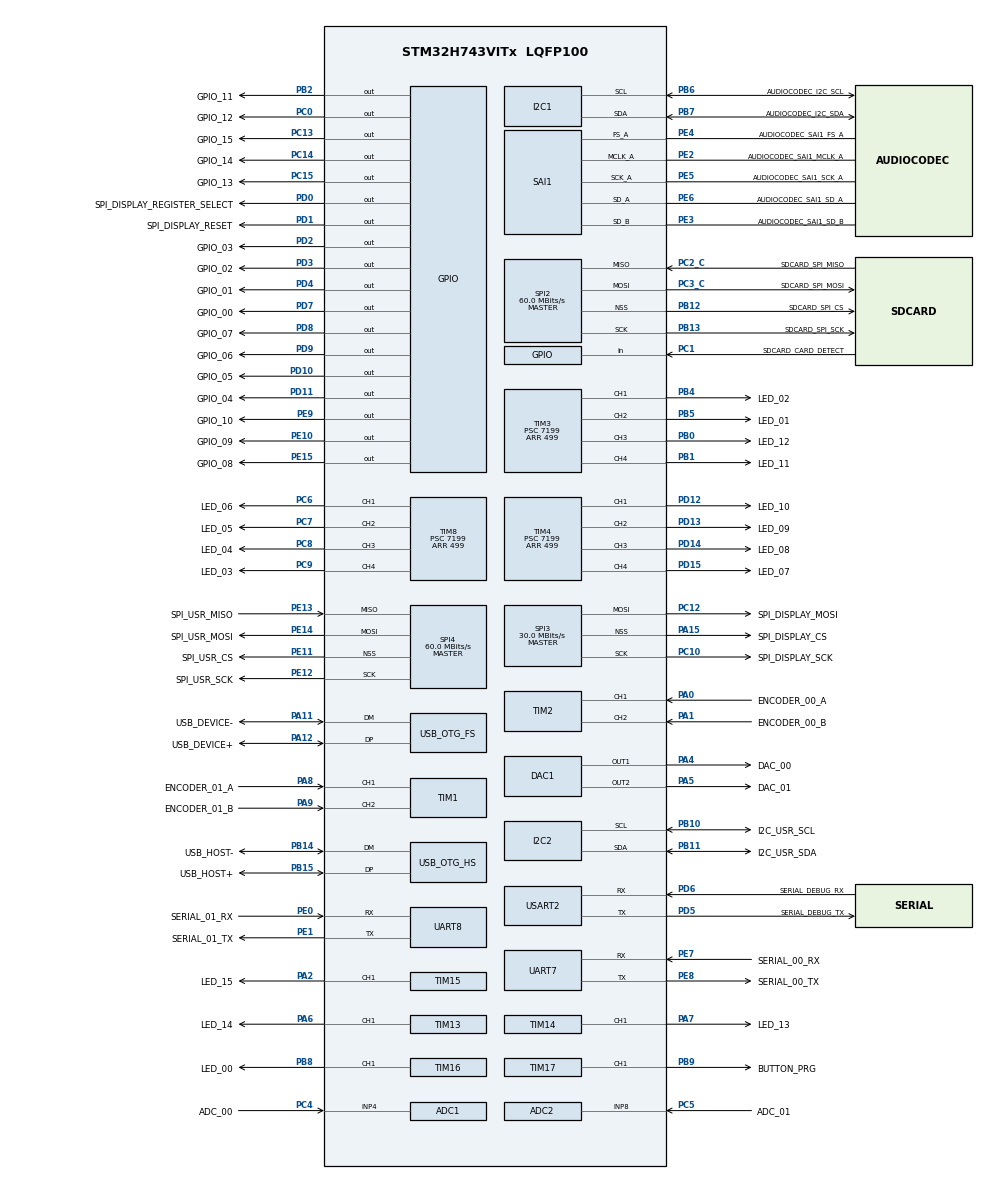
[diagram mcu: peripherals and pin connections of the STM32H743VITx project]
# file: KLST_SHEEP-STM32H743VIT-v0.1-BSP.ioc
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ADC1.Channel-5\#ChannelRegularConversion=ADC_CHANNEL_4
ADC1.NbrOfConversionFlag=1
ADC1.OffsetNumber-5\#ChannelRegularConversion=ADC_OFFSET_NONE
ADC1.OffsetSignedSaturation-5\#ChannelRegularConversion=DISABLE
ADC1.Rank-5\#ChannelRegularConversion=1
ADC1.SamplingTime-5\#ChannelRegularConversion=ADC_SAMPLETIME_1CYCLE_5
ADC1.master=1
ADC2.Channel-4\#ChannelRegularConversion=ADC_CHANNEL_8
ADC2.NbrOfConversionFlag=1
ADC2.OffsetNumber-4\#ChannelRegularConversion=ADC_OFFSET_NONE
ADC2.OffsetSignedSaturation-4\#ChannelRegularConversion=DISABLE
ADC2.Rank-4\#ChannelRegularConversion=1
ADC2.SamplingTime-4\#ChannelRegularConversion=ADC_SAMPLETIME_1CYCLE_5
DAC1.DAC_Channel-DAC_OUT1=DAC_CHANNEL_1
DAC1.DAC_Channel-DAC_OUT2=DAC_CHANNEL_2
Dma.Request0=SAI1_A
Dma.Request1=SAI1_B
Dma.Request2=SPI3_TX
Dma.SAI1_A.0.Direction=DMA_MEMORY_TO_PERIPH
Dma.SAI1_A.0.EventEnable=DISABLE
Dma.SAI1_A.0.FIFOMode=DMA_FIFOMODE_DISABLE
Dma.SAI1_A.0.Instance=DMA1_Stream0
Dma.SAI1_A.0.MemDataAlignment=DMA_MDATAALIGN_HALFWORD
Dma.SAI1_A.0.MemInc=DMA_MINC_ENABLE
Dma.SAI1_A.0.Mode=DMA_CIRCULAR
Dma.SAI1_A.0.PeriphDataAlignment=DMA_PDATAALIGN_HALFWORD
Dma.SAI1_A.0.PeriphInc=DMA_PINC_DISABLE
Dma.SAI1_A.0.Polarity=HAL_DMAMUX_REQ_GEN_RISING
Dma.SAI1_A.0.Priority=DMA_PRIORITY_LOW
Dma.SAI1_A.0.RequestNumber=1
Dma.SAI1_A.0.SignalID=NONE
Dma.SAI1_A.0.SyncEnable=DISABLE
Dma.SAI1_A.0.SyncPolarity=HAL_DMAMUX_SYNC_NO_EVENT
Dma.SAI1_A.0.SyncRequestNumber=1
Dma.SAI1_A.0.SyncSignalID=NONE
Dma.SAI1_B.1.Direction=DMA_PERIPH_TO_MEMORY
Dma.SAI1_B.1.EventEnable=DISABLE
Dma.SAI1_B.1.FIFOMode=DMA_FIFOMODE_DISABLE
Dma.SAI1_B.1.Instance=DMA1_Stream1
Dma.SAI1_B.1.MemDataAlignment=DMA_MDATAALIGN_HALFWORD
Dma.SAI1_B.1.MemInc=DMA_MINC_ENABLE
Dma.SAI1_B.1.Mode=DMA_CIRCULAR
Dma.SAI1_B.1.PeriphDataAlignment=DMA_PDATAALIGN_HALFWORD
Dma.SAI1_B.1.PeriphInc=DMA_PINC_DISABLE
Dma.SAI1_B.1.Polarity=HAL_DMAMUX_REQ_GEN_RISING
Dma.SAI1_B.1.Priority=DMA_PRIORITY_LOW
Dma.SAI1_B.1.RequestNumber=1
Dma.SAI1_B.1.SignalID=NONE
Dma.SAI1_B.1.SyncEnable=DISABLE
Dma.SAI1_B.1.SyncPolarity=HAL_DMAMUX_SYNC_NO_EVENT
Dma.SAI1_B.1.SyncRequestNumber=1
Dma.SAI1_B.1.SyncSignalID=NONE
Dma.SPI3_TX.2.Direction=DMA_MEMORY_TO_PERIPH
Dma.SPI3_TX.2.EventEnable=DISABLE
Dma.SPI3_TX.2.FIFOMode=DMA_FIFOMODE_DISABLE
Dma.SPI3_TX.2.Instance=DMA2_Stream0
Dma.SPI3_TX.2.MemDataAlignment=DMA_MDATAALIGN_BYTE
Dma.SPI3_TX.2.MemInc=DMA_MINC_ENABLE
Dma.SPI3_TX.2.Mode=DMA_NORMAL
Dma.SPI3_TX.2.PeriphDataAlignment=DMA_PDATAALIGN_BYTE
Dma.SPI3_TX.2.PeriphInc=DMA_PINC_DISABLE
Dma.SPI3_TX.2.Polarity=HAL_DMAMUX_REQ_GEN_RISING
Dma.SPI3_TX.2.Priority=DMA_PRIORITY_LOW
Dma.SPI3_TX.2.RequestNumber=1
Dma.SPI3_TX.2.SignalID=NONE
Dma.SPI3_TX.2.SyncEnable=DISABLE
Dma.SPI3_TX.2.SyncPolarity=HAL_DMAMUX_SYNC_NO_EVENT
Dma.SPI3_TX.2.SyncRequestNumber=1
Dma.SPI3_TX.2.SyncSignalID=NONE
Mcu.Family=STM32H7
Mcu.Name=STM32H743VITx
Mcu.Package=LQFP100
NVIC.DMA1_Stream0_IRQn=true\:0\:0\:false\:false\:true\:false\:true\:true
NVIC.DMA1_Stream1_IRQn=true\:0\:0\:false\:false\:true\:false\:true\:true
NVIC.DMA2_Stream0_IRQn=true\:0\:0\:false\:false\:true\:false\:true\:true
NVIC.OTG_FS_IRQn=true\:0\:0\:false\:false\:true\:false\:true\:true
NVIC.OTG_HS_IRQn=true\:0\:0\:false\:false\:true\:false\:true\:true
NVIC.PriorityGroup=NVIC_PRIORITYGROUP_4
NVIC.SPI3_IRQn=true\:0\:0\:false\:false\:true\:false\:true\:true
PA0.GPIO_Label=ENCODER_00_A
PA0.Signal=S_TIM2_CH1_ETR
PA1.GPIO_Label=ENCODER_00_B
PA1.Signal=S_TIM2_CH2
PA10.GPIO_Label=ENCODER_01_BUTTON
PA10.Signal=S_TIM1_CH3
PA11.GPIO_Label=USB_DEVICE-
PA11.Mode=Device_Only
PA11.Signal=USB_OTG_FS_DM
PA12.GPIO_Label=USB_DEVICE+
PA12.Mode=Device_Only
PA12.Signal=USB_OTG_FS_DP
PA13\ (JTMS/SWDIO).GPIO_Label=SWD_SWDIO
PA13\ (JTMS/SWDIO).Mode=Trace_Asynchronous_SW
PA13\ (JTMS/SWDIO).Signal=DEBUG_JTMS-SWDIO
PA14\ (JTCK/SWCLK).GPIO_Label=SWD_SWCLK
PA14\ (JTCK/SWCLK).Mode=Trace_Asynchronous_SW
PA14\ (JTCK/SWCLK).Signal=DEBUG_JTCK-SWCLK
PA15\ (JTDI).GPIO_Label=SPI_DISPLAY_CS
PA15\ (JTDI).Mode=NSS_Signal_Hard_Output
PA15\ (JTDI).Signal=SPI3_NSS
PA2.GPIO_Label=LED_15
PA2.Signal=S_TIM15_CH1
PA3.GPIO_Label=ENCODER_00_BUTTON
PA3.Signal=S_TIM2_CH4
PA4.GPIO_Label=DAC_00
PA4.Signal=COMP_DAC11_group
PA5.GPIO_Label=DAC_01
PA5.Signal=COMP_DAC12_group
PA6.GPIO_Label=LED_14
PA6.Signal=S_TIM13_CH1
PA7.GPIO_Label=LED_13
PA7.Signal=S_TIM14_CH1
PA8.GPIO_Label=ENCODER_01_A
PA8.Signal=S_TIM1_CH1
PA9.GPIO_Label=ENCODER_01_B
PA9.Signal=S_TIM1_CH2
PB0.GPIO_Label=LED_12
PB0.Signal=S_TIM3_CH3
PB1.GPIO_Label=LED_11
PB1.Signal=S_TIM3_CH4
PB10.GPIO_Label=I2C_USR_SCL
PB10.GPIO_Pu=GPIO_PULLUP
PB10.Mode=I2C
PB10.Signal=I2C2_SCL
PB11.GPIO_Label=I2C_USR_SDA
PB11.GPIO_Pu=GPIO_NOPULL
PB11.Mode=I2C
PB11.Signal=I2C2_SDA
PB12.GPIO_Label=SDCARD_SPI_CS
PB12.Mode=NSS_Signal_Hard_Output
PB12.Signal=SPI2_NSS
PB13.GPIO_Label=SDCARD_SPI_SCK
PB13.Mode=Full_Duplex_Master
PB13.Signal=SPI2_SCK
PB14.GPIO_Label=USB_HOST-
PB14.Mode=Host_FS
PB14.Signal=USB_OTG_HS_DM
PB15.GPIO_Label=USB_HOST+
PB15.Mode=Host_FS
PB15.Signal=USB_OTG_HS_DP
PB2.GPIO_Label=GPIO_11
PB2.Signal=GPIO_Output
PB3\ (JTDO/TRACESWO).GPIO_Label=SWD_SWO
PB3\ (JTDO/TRACESWO).Mode=Trace_Asynchronous_SW
PB3\ (JTDO/TRACESWO).Signal=DEBUG_JTDO-SWO
PB4\ (NJTRST).GPIO_Label=LED_02
PB4\ (NJTRST).Signal=S_TIM3_CH1
PB5.GPIO_Label=LED_01
PB5.Signal=S_TIM3_CH2
PB6.GPIO_Label=AUDIOCODEC_I2C_SCL
PB6.GPIO_Pu=GPIO_PULLUP
PB6.GPIO_Speed=GPIO_SPEED_FREQ_HIGH
PB6.Mode=I2C
PB6.Signal=I2C1_SCL
PB7.GPIO_Label=AUDIOCODEC_I2C_SDA
PB7.GPIO_Pu=GPIO_PULLUP
PB7.GPIO_Speed=GPIO_SPEED_FREQ_HIGH
PB7.Mode=I2C
PB7.Signal=I2C1_SDA
PB8.GPIO_Label=LED_00
PB8.Signal=S_TIM16_CH1
PB9.GPIO_Label=BUTTON_PRG
PB9.Signal=S_TIM17_CH1
PC0.GPIO_Label=GPIO_12
PC0.Signal=GPIO_Output
PC1.GPIO_Label=SDCARD_CARD_DETECT
PC1.Signal=GPIO_Input
PC10.GPIO_Label=SPI_DISPLAY_SCK
PC10.Mode=TX_Only_Simplex_Unidirect_Master
PC10.Signal=SPI3_SCK
PC11.GPIO_Label=SPI_DISPLAY_MISO
PC11.Signal=SPI3_MISO
PC12.GPIO_Label=SPI_DISPLAY_MOSI
PC12.Mode=TX_Only_Simplex_Unidirect_Master
PC12.Signal=SPI3_MOSI
PC13.GPIO_Label=GPIO_15
PC13.Signal=GPIO_Output
PC14-OSC32_IN\ (OSC32_IN).GPIO_Label=GPIO_14
PC14-OSC32_IN\ (OSC32_IN).Signal=GPIO_Output
PC15-OSC32_OUT\ (OSC32_OUT).GPIO_Label=GPIO_13
PC15-OSC32_OUT\ (OSC32_OUT).Signal=GPIO_Output
PC2_C.GPIO_Label=SDCARD_SPI_MISO
PC2_C.Mode=Full_Duplex_Master
PC2_C.Signal=SPI2_MISO
PC3_C.GPIO_Label=SDCARD_SPI_MOSI
PC3_C.Mode=Full_Duplex_Master
PC3_C.Signal=SPI2_MOSI
PC4.GPIO_Label=ADC_00
PC4.Signal=ADCx_INP4
PC5.GPIO_Label=ADC_01
PC5.Signal=ADCx_INP8
PC6.GPIO_Label=LED_06
PC6.Signal=S_TIM8_CH1
PC7.GPIO_Label=LED_05
PC7.Signal=S_TIM8_CH2
PC8.GPIO_Label=LED_04
PC8.Signal=S_TIM8_CH3
PC9.GPIO_Label=LED_03
PC9.Signal=S_TIM8_CH4
PD0.GPIO_Label=SPI_DISPLAY_REGISTER_SELECT
PD0.Signal=GPIO_Output
PD1.GPIO_Label=SPI_DISPLAY_RESET
PD1.Signal=GPIO_Output
PD10.GPIO_Label=GPIO_05
PD10.Signal=GPIO_Output
PD11.GPIO_Label=GPIO_04
PD11.Signal=GPIO_Output
PD12.GPIO_Label=LED_10
PD12.Signal=S_TIM4_CH1
PD13.GPIO_Label=LED_09
PD13.Signal=S_TIM4_CH2
PD14.GPIO_Label=LED_08
PD14.Signal=S_TIM4_CH3
PD15.GPIO_Label=LED_07
PD15.Signal=S_TIM4_CH4
PD2.GPIO_Label=GPIO_03
PD2.Signal=GPIO_Output
PD3.GPIO_Label=GPIO_02
PD3.Signal=GPIO_Output
PD4.GPIO_Label=GPIO_01
PD4.Signal=GPIO_Output
PD5.GPIO_Label=SERIAL_DEBUG_TX
PD5.Mode=Asynchronous
PD5.Signal=USART2_TX
PD6.GPIO_Label=SERIAL_DEBUG_RX
PD6.Mode=Asynchronous
PD6.Signal=USART2_RX
PD7.GPIO_Label=GPIO_00
PD7.Signal=GPIO_Output
PD8.GPIO_Label=GPIO_07
PD8.Signal=GPIO_Output
PD9.GPIO_Label=GPIO_06
PD9.Signal=GPIO_Output
PE0.GPIO_Label=SERIAL_01_RX
PE0.Mode=Asynchronous
PE0.Signal=UART8_RX
PE1.GPIO_Label=SERIAL_01_TX
PE1.Mode=Asynchronous
PE1.Signal=UART8_TX
PE10.GPIO_Label=GPIO_09
PE10.Signal=GPIO_Output
PE11.GPIO_Label=SPI_USR_CS
PE11.Mode=NSS_Signal_Hard_Output
PE11.Signal=SPI4_NSS
PE12.GPIO_Label=SPI_USR_SCK
PE12.Mode=Full_Duplex_Master
PE12.Signal=SPI4_SCK
PE13.GPIO_Label=SPI_USR_MISO
PE13.Mode=Full_Duplex_Master
PE13.Signal=SPI4_MISO
PE14.GPIO_Label=SPI_USR_MOSI
PE14.Mode=Full_Duplex_Master
PE14.Signal=SPI4_MOSI
PE15.GPIO_Label=GPIO_08
PE15.Signal=GPIO_Output
PE2.GPIO_Label=AUDIOCODEC_SAI1_MCLK_A
PE2.Mode=SAI_A_MasterWithClock
PE2.Signal=SAI1_MCLK_A
PE3.GPIO_Label=AUDIOCODEC_SAI1_SD_B
PE3.Mode=SAI_B_SyncSlave
PE3.Signal=SAI1_SD_B
PE4.GPIO_Label=AUDIOCODEC_SAI1_FS_A
PE4.Mode=SAI_A_MasterWithClock
PE4.Signal=SAI1_FS_A
PE5.GPIO_Label=AUDIOCODEC_SAI1_SCK_A
PE5.Mode=SAI_A_MasterWithClock
PE5.Signal=SAI1_SCK_A
PE6.GPIO_Label=AUDIOCODEC_SAI1_SD_A
PE6.Mode=SAI_A_MasterWithClock
PE6.Signal=SAI1_SD_A
PE7.GPIO_Label=SERIAL_00_RX
PE7.Mode=Asynchronous
PE7.Signal=UART7_RX
PE8.GPIO_Label=SERIAL_00_TX
PE8.Mode=Asynchronous
PE8.Signal=UART7_TX
PE9.GPIO_Label=GPIO_10
PE9.Signal=GPIO_Output
PH0-OSC_IN\ (PH0).GPIO_Label=RCC_OSC_IN
PH0-OSC_IN\ (PH0).Mode=HSE-External-Oscillator
PH0-OSC_IN\ (PH0).Signal=RCC_OSC_IN
PH1-OSC_OUT\ (PH1).GPIO_Label=RCC_OSC_OUT
PH1-OSC_OUT\ (PH1).Mode=HSE-External-Oscillator
PH1-OSC_OUT\ (PH1).Signal=RCC_OSC_OUT
ProjectManager.HeapSize=0x200
ProjectManager.StackSize=0x400
ProjectManager.TargetToolchain=STM32CubeIDE
RCC.ADCCLockSelection=RCC_ADCCLKSOURCE_PLL3
RCC.ADCFreq_Value=120000000
RCC.APB1Freq_Value=120000000
RCC.APB2Freq_Value=120000000
RCC.APB3Freq_Value=120000000
RCC.APB4Freq_Value=120000000
RCC.CortexFreq_Value=480000000
RCC.D1PPRE=RCC_APB3_DIV2
RCC.D2PPRE1=RCC_APB1_DIV2
RCC.D2PPRE2=RCC_APB2_DIV2
RCC.D3PPRE=RCC_APB4_DIV2
RCC.DIVM1=2
RCC.DIVM2=8
RCC.DIVM3=8
RCC.DIVN1=120
RCC.DIVN2=123
RCC.DIVN3=120
RCC.HCLKFreq_Value=240000000
RCC.HPRE=RCC_HCLK_DIV2
RCC.HSE_VALUE=16000000
RCC.I2C123CLockSelection=RCC_I2C123CLKSOURCE_HSI
RCC.PLL2_VCI_Range-AdvancedSettings=RCC_PLL2VCIRANGE_3
RCC.PLLSourceVirtual=RCC_PLLSOURCE_HSE
RCC.SAI1CLockSelection=RCC_SAI1CLKSOURCE_PLL2
RCC.SAI23CLockSelection=RCC_SAI23CLKSOURCE_PLL3
RCC.SPI123CLockSelection=RCC_SPI123CLKSOURCE_PLL3
RCC.SYSCLKFreq_VALUE=480000000
RCC.SYSCLKSource=RCC_SYSCLKSOURCE_PLLCLK
RCC.Spi45ClockSelection=RCC_SPI45CLKSOURCE_PLL3
RCC.USBCLockSelection=RCC_USBCLKSOURCE_HSI48
RCC.USBFreq_Value=48000000
SAI1.AudioFrequency-SAI_A_MasterWithClock=SAI_AUDIO_FREQUENCY_48K
SAI1.ErrorAudioFreq-SAI_A_MasterWithClock=0.09 %
SAI1.InitProtocol-SAI_A_MasterWithClock=Enable
SAI1.InitProtocol-SAI_B_SyncSlave=Enable
SAI1.Instance-SAI_A_MasterWithClock=SAI$Index_Block_A
SAI1.Instance-SAI_B_SyncSlave=SAI$Index_Block_B
SAI1.MClockEnable=SAI_MASTERCLOCK_ENABLE
SAI1.RealAudioFreq-SAI_A_MasterWithClock=48.046 KHz
SAI1.VirtualMode-SAI_A_MasterWithClock=VM_MASTER
SAI1.VirtualMode-SAI_B_SyncSlave=VM_SLAVE
SAI1.VirtualProtocol-SAI_A_BASIC=VM_BASIC_PROTOCOL
SAI1.VirtualProtocol-SAI_B_BASIC=VM_BASIC_PROTOCOL
SH.ADCx_INP4.0=ADC1_INP4,IN4-Single-Ended
SH.ADCx_INP8.0=ADC2_INP8,IN8-Single-Ended
SH.COMP_DAC11_group.0=DAC1_OUT1,DAC_OUT1
SH.COMP_DAC12_group.0=DAC1_OUT2,DAC_OUT2
SH.S_TIM13_CH1.0=TIM13_CH1,PWM Generation1 CH1
SH.S_TIM14_CH1.0=TIM14_CH1,PWM Generation1 CH1
SH.S_TIM15_CH1.0=TIM15_CH1,PWM Generation1 CH1
SH.S_TIM16_CH1.0=TIM16_CH1,PWM Generation1 CH1
SH.S_TIM17_CH1.0=TIM17_CH1,PWM Generation1 CH1
SH.S_TIM1_CH1.0=TIM1_CH1,Encoder_Interface
SH.S_TIM1_CH2.0=TIM1_CH2,Encoder_Interface
SH.S_TIM1_CH3.0=TIM1_CH3
SH.S_TIM2_CH1_ETR.0=TIM2_CH1,Encoder_Interface
SH.S_TIM2_CH2.0=TIM2_CH2,Encoder_Interface
SH.S_TIM2_CH4.0=TIM2_CH4
SH.S_TIM3_CH1.0=TIM3_CH1,PWM Generation1 CH1
SH.S_TIM3_CH2.0=TIM3_CH2,PWM Generation2 CH2
SH.S_TIM3_CH3.0=TIM3_CH3,PWM Generation3 CH3
SH.S_TIM3_CH4.0=TIM3_CH4,PWM Generation4 CH4
SH.S_TIM4_CH1.0=TIM4_CH1,PWM Generation1 CH1
SH.S_TIM4_CH2.0=TIM4_CH2,PWM Generation2 CH2
SH.S_TIM4_CH3.0=TIM4_CH3,PWM Generation3 CH3
SH.S_TIM4_CH4.0=TIM4_CH4,PWM Generation4 CH4
SH.S_TIM8_CH1.0=TIM8_CH1,PWM Generation1 CH1
SH.S_TIM8_CH2.0=TIM8_CH2,PWM Generation2 CH2
SH.S_TIM8_CH3.0=TIM8_CH3,PWM Generation3 CH3
SH.S_TIM8_CH4.0=TIM8_CH4,PWM Generation4 CH4
SPI2.BaudRatePrescaler=SPI_BAUDRATEPRESCALER_2
SPI2.CalculateBaudRate=60.0 MBits/s
SPI2.Direction=SPI_DIRECTION_2LINES
SPI2.Mode=SPI_MODE_MASTER
SPI2.VirtualNSS=VM_NSSHARD
SPI2.VirtualType=VM_MASTER
SPI3.BaudRatePrescaler=SPI_BAUDRATEPRESCALER_4
SPI3.CalculateBaudRate=30.0 MBits/s
SPI3.DataSize=SPI_DATASIZE_8BIT
SPI3.Direction=SPI_DIRECTION_2LINES_TXONLY
SPI3.MasterKeepIOState=SPI_MASTER_KEEP_IO_STATE_ENABLE
SPI3.Mode=SPI_MODE_MASTER
SPI3.VirtualNSS=VM_NSSHARD
SPI3.VirtualType=VM_MASTER
SPI4.CalculateBaudRate=60.0 MBits/s
SPI4.Direction=SPI_DIRECTION_2LINES
SPI4.Mode=SPI_MODE_MASTER
SPI4.VirtualNSS=VM_NSSHARD
SPI4.VirtualType=VM_MASTER
TIM1.IC1Filter=7
TIM1.IC2Filter=7
TIM13.Channel=TIM_CHANNEL_1
TIM13.Period=499
TIM13.Prescaler=7199
TIM14.Channel=TIM_CHANNEL_1
TIM14.Period=499
TIM14.Prescaler=7199
TIM15.Channel-PWM\ Generation1\ CH1=TIM_CHANNEL_1
TIM15.Period=499
TIM15.Prescaler=7199
TIM16.Channel=TIM_CHANNEL_1
TIM16.OCIdleState_1=TIM_OCIDLESTATE_SET
TIM16.Period=499
TIM16.Prescaler=7199
TIM16.Pulse=250
TIM17.Channel=TIM_CHANNEL_1
TIM2.IC1Filter=7
TIM2.IC2Filter=7
TIM3.Channel-PWM\ Generation1\ CH1=TIM_CHANNEL_1
TIM3.Channel-PWM\ Generation2\ CH2=TIM_CHANNEL_2
TIM3.Channel-PWM\ Generation3\ CH3=TIM_CHANNEL_3
TIM3.Channel-PWM\ Generation4\ CH4=TIM_CHANNEL_4
TIM3.Period=499
TIM3.Prescaler=7199
TIM4.Channel-PWM\ Generation1\ CH1=TIM_CHANNEL_1
TIM4.Channel-PWM\ Generation2\ CH2=TIM_CHANNEL_2
TIM4.Channel-PWM\ Generation3\ CH3=TIM_CHANNEL_3
TIM4.Channel-PWM\ Generation4\ CH4=TIM_CHANNEL_4
TIM4.Period=499
TIM4.Prescaler=7199
TIM8.Channel-PWM\ Generation1\ CH1=TIM_CHANNEL_1
TIM8.Channel-PWM\ Generation2\ CH2=TIM_CHANNEL_2
TIM8.Channel-PWM\ Generation3\ CH3=TIM_CHANNEL_3
TIM8.Channel-PWM\ Generation4\ CH4=TIM_CHANNEL_4
TIM8.Period=499
TIM8.Prescaler=7199
USART2.VirtualMode-Asynchronous=VM_ASYNC
USB_DEVICE.CLASS_NAME_FS=HID
USB_DEVICE.USBD_DEBUG_LEVEL-HID_FS=3
USB_DEVICE.VirtualMode-HID_FS=Hid
USB_DEVICE.VirtualModeFS=Hid_FS
USB_HOST.BSP.number=1
USB_HOST.USBH_DEBUG_LEVEL-HID_HS=3
USB_HOST.USBH_HandleTypeDef-HID_HS=hUsbHostHS
USB_HOST.VirtualModeHS=Hid
USB_HOST0.BSP.STBoard=false
USB_HOST0.BSP.api=Unknown
USB_HOST0.BSP.instance=PD7
USB_HOST0.BSP.ip=GPIO
USB_HOST0.BSP.mode=Output
USB_HOST0.BSP.name=Drive_VBUS_HS
USB_HOST0.BSP.solution=PD7
USB_OTG_FS.VirtualMode=Device_Only
USB_OTG_HS.VirtualMode-Host_FS=Host_FS
VP_SAI1_VP_$IpInstance_SAIA_SAI_BASIC.Mode=SAI_A_BASIC
VP_SAI1_VP_$IpInstance_SAIB_SAI_BASIC.Mode=SAI_B_BASIC
VP_TIM13_VS_ClockSourceINT.Mode=Enable_Timer
VP_TIM14_VS_ClockSourceINT.Mode=Enable_Timer
VP_TIM16_VS_ClockSourceINT.Mode=Enable_Timer
VP_TIM17_VS_ClockSourceINT.Mode=Enable_Timer
VP_USB_DEVICE_VS_USB_DEVICE_HID_FS.Mode=HID_FS
VP_USB_HOST_VS_USB_HOST_HID_HS.Mode=HID_HS
board=custom

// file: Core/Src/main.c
/* USER CODE BEGIN Header */
/**
  ******************************************************************************
  * @file           : main.c
  * @brief          : Main program body
  ******************************************************************************
  * @attention
  *
  * <h2><center>&copy; Copyright (c) 2021 STMicroelectronics.
  * All rights reserved.</center></h2>
  *
  * This software component is licensed by ST under BSD 3-Clause license,
  * the "License"; You may not use this file except in compliance with the
  * License. You may obtain a copy of the License at:
  *                        opensource.org/licenses/BSD-3-Clause
  *
  ******************************************************************************
  */
/* USER CODE END Header */
#include "main.h"
#include "usb_device.h"
#include "usb_host.h"

ADC_HandleTypeDef hadc1;
ADC_HandleTypeDef hadc2;

DAC_HandleTypeDef hdac1;

I2C_HandleTypeDef hi2c1;
I2C_HandleTypeDef hi2c2;

SAI_HandleTypeDef hsai_BlockA1;
SAI_HandleTypeDef hsai_BlockB1;
DMA_HandleTypeDef hdma_sai1_a;
DMA_HandleTypeDef hdma_sai1_b;

SPI_HandleTypeDef hspi2;
SPI_HandleTypeDef hspi3;
SPI_HandleTypeDef hspi4;
DMA_HandleTypeDef hdma_spi3_tx;

TIM_HandleTypeDef htim1;
TIM_HandleTypeDef htim2;
TIM_HandleTypeDef htim3;
TIM_HandleTypeDef htim4;
TIM_HandleTypeDef htim8;
TIM_HandleTypeDef htim13;
TIM_HandleTypeDef htim14;
TIM_HandleTypeDef htim15;
TIM_HandleTypeDef htim16;
TIM_HandleTypeDef htim17;

UART_HandleTypeDef huart7;
UART_HandleTypeDef huart8;
UART_HandleTypeDef huart2;

void SystemClock_Config(void);
void PeriphCommonClock_Config(void);
static void MX_GPIO_Init(void);
static void MX_I2C1_Init(void);
static void MX_SPI2_Init(void);
static void MX_TIM2_Init(void);
static void MX_UART7_Init(void);
static void MX_UART8_Init(void);
static void MX_I2C2_Init(void);
static void MX_SPI4_Init(void);
static void MX_DAC1_Init(void);
static void MX_SAI1_Init(void);
static void MX_TIM1_Init(void);
static void MX_DMA_Init(void);
static void MX_ADC1_Init(void);
static void MX_ADC2_Init(void);
static void MX_TIM4_Init(void);
static void MX_TIM8_Init(void);
static void MX_TIM13_Init(void);
static void MX_TIM14_Init(void);
static void MX_TIM15_Init(void);
static void MX_USART2_UART_Init(void);
static void MX_SPI3_Init(void);
static void MX_TIM3_Init(void);
static void MX_TIM16_Init(void);
static void MX_TIM17_Init(void);
void MX_USB_HOST_Process(void);

/* USER CODE BEGIN PFP */
extern void setup();
extern void loop();
/* USER CODE END PFP */

int main(void)
{

  /* MCU Configuration--------------------------------------------------------*/

  /* Reset of all peripherals, Initializes the Flash interface and the Systick. */
  HAL_Init();

  /* Configure the system clock */
  SystemClock_Config();

/* Configure the peripherals common clocks */
  PeriphCommonClock_Config();

  /* Initialize all configured peripherals */
  MX_GPIO_Init();
  MX_I2C1_Init();
  MX_SPI2_Init();
  MX_TIM2_Init();
  MX_UART7_Init();
  MX_UART8_Init();
  MX_I2C2_Init();
  MX_SPI4_Init();
  MX_DAC1_Init();
  MX_SAI1_Init();
  MX_TIM1_Init();
  MX_DMA_Init();
  MX_ADC1_Init();
  MX_ADC2_Init();
  MX_TIM4_Init();
  MX_TIM8_Init();
  MX_TIM13_Init();
  MX_TIM14_Init();
  MX_TIM15_Init();
  MX_USART2_UART_Init();
  MX_SPI3_Init();
  MX_TIM3_Init();
  MX_TIM16_Init();
  MX_TIM17_Init();
  MX_USB_HOST_Init();
  MX_USB_DEVICE_Init();
  /* USER CODE BEGIN 2 */
  setup();
  /* USER CODE END 2 */

  /* Infinite loop */
  while (1)
  {
    MX_USB_HOST_Process();

    /* USER CODE BEGIN 3 */
	loop();
  }
  /* USER CODE END 3 */
}

void SystemClock_Config(void)
{
  RCC_OscInitTypeDef RCC_OscInitStruct = {0};
  RCC_ClkInitTypeDef RCC_ClkInitStruct = {0};

  /** Supply configuration update enable
  */
  HAL_PWREx_ConfigSupply(PWR_LDO_SUPPLY);

  /** Configure the main internal regulator output voltage
  */
  __HAL_PWR_VOLTAGESCALING_CONFIG(PWR_REGULATOR_VOLTAGE_SCALE1);

  while(!__HAL_PWR_GET_FLAG(PWR_FLAG_VOSRDY)) {}

  __HAL_RCC_SYSCFG_CLK_ENABLE();
  __HAL_PWR_VOLTAGESCALING_CONFIG(PWR_REGULATOR_VOLTAGE_SCALE0);

  while(!__HAL_PWR_GET_FLAG(PWR_FLAG_VOSRDY)) {}

  /** Macro to configure the PLL clock source
  */
  __HAL_RCC_PLL_PLLSOURCE_CONFIG(RCC_PLLSOURCE_HSE);

  /** Initializes the RCC Oscillators according to the specified parameters
  * in the RCC_OscInitTypeDef structure.
  */
  RCC_OscInitStruct.OscillatorType = RCC_OSCILLATORTYPE_HSI48|RCC_OSCILLATORTYPE_HSI
                              |RCC_OSCILLATORTYPE_HSE;
  RCC_OscInitStruct.HSEState = RCC_HSE_ON;
  RCC_OscInitStruct.HSIState = RCC_HSI_DIV1;
  RCC_OscInitStruct.HSICalibrationValue = RCC_HSICALIBRATION_DEFAULT;
  RCC_OscInitStruct.HSI48State = RCC_HSI48_ON;
  RCC_OscInitStruct.PLL.PLLState = RCC_PLL_ON;
  RCC_OscInitStruct.PLL.PLLSource = RCC_PLLSOURCE_HSE;
  RCC_OscInitStruct.PLL.PLLM = 2;
  RCC_OscInitStruct.PLL.PLLN = 120;
  RCC_OscInitStruct.PLL.PLLP = 2;
  RCC_OscInitStruct.PLL.PLLQ = 2;
  RCC_OscInitStruct.PLL.PLLR = 2;
  RCC_OscInitStruct.PLL.PLLRGE = RCC_PLL1VCIRANGE_3;
  RCC_OscInitStruct.PLL.PLLVCOSEL = RCC_PLL1VCOWIDE;
  RCC_OscInitStruct.PLL.PLLFRACN = 0;
  if (HAL_RCC_OscConfig(&RCC_OscInitStruct) != HAL_OK)
  {
    Error_Handler();
  }

  /** Initializes the CPU, AHB and APB buses clocks
  */
  RCC_ClkInitStruct.ClockType = RCC_CLOCKTYPE_HCLK|RCC_CLOCKTYPE_SYSCLK
                              |RCC_CLOCKTYPE_PCLK1|RCC_CLOCKTYPE_PCLK2
                              |RCC_CLOCKTYPE_D3PCLK1|RCC_CLOCKTYPE_D1PCLK1;
  RCC_ClkInitStruct.SYSCLKSource = RCC_SYSCLKSOURCE_PLLCLK;
  RCC_ClkInitStruct.SYSCLKDivider = RCC_SYSCLK_DIV1;
  RCC_ClkInitStruct.AHBCLKDivider = RCC_HCLK_DIV2;
  RCC_ClkInitStruct.APB3CLKDivider = RCC_APB3_DIV2;
  RCC_ClkInitStruct.APB1CLKDivider = RCC_APB1_DIV2;
  RCC_ClkInitStruct.APB2CLKDivider = RCC_APB2_DIV2;
  RCC_ClkInitStruct.APB4CLKDivider = RCC_APB4_DIV2;

  if (HAL_RCC_ClockConfig(&RCC_ClkInitStruct, FLASH_LATENCY_4) != HAL_OK)
  {
    Error_Handler();
  }
}

void PeriphCommonClock_Config(void)
{
  RCC_PeriphCLKInitTypeDef PeriphClkInitStruct = {0};

  /** Initializes the peripherals clock
  */
  PeriphClkInitStruct.PeriphClockSelection = RCC_PERIPHCLK_ADC|RCC_PERIPHCLK_SAI1
                              |RCC_PERIPHCLK_SPI3|RCC_PERIPHCLK_SPI2
                              |RCC_PERIPHCLK_SPI4;
  PeriphClkInitStruct.PLL2.PLL2M = 8;
  PeriphClkInitStruct.PLL2.PLL2N = 123;
  PeriphClkInitStruct.PLL2.PLL2P = 2;
  PeriphClkInitStruct.PLL2.PLL2Q = 2;
  PeriphClkInitStruct.PLL2.PLL2R = 2;
  PeriphClkInitStruct.PLL2.PLL2RGE = RCC_PLL2VCIRANGE_1;
  PeriphClkInitStruct.PLL2.PLL2VCOSEL = RCC_PLL2VCOWIDE;
  PeriphClkInitStruct.PLL2.PLL2FRACN = 0;
  PeriphClkInitStruct.PLL3.PLL3M = 8;
  PeriphClkInitStruct.PLL3.PLL3N = 120;
  PeriphClkInitStruct.PLL3.PLL3P = 2;
  PeriphClkInitStruct.PLL3.PLL3Q = 2;
  PeriphClkInitStruct.PLL3.PLL3R = 2;
  PeriphClkInitStruct.PLL3.PLL3RGE = RCC_PLL3VCIRANGE_1;
  PeriphClkInitStruct.PLL3.PLL3VCOSEL = RCC_PLL3VCOWIDE;
  PeriphClkInitStruct.PLL3.PLL3FRACN = 0;
  PeriphClkInitStruct.Sai1ClockSelection = RCC_SAI1CLKSOURCE_PLL2;
  PeriphClkInitStruct.Spi123ClockSelection = RCC_SPI123CLKSOURCE_PLL3;
  PeriphClkInitStruct.Spi45ClockSelection = RCC_SPI45CLKSOURCE_PLL3;
  PeriphClkInitStruct.AdcClockSelection = RCC_ADCCLKSOURCE_PLL3;
  if (HAL_RCCEx_PeriphCLKConfig(&PeriphClkInitStruct) != HAL_OK)
  {
    Error_Handler();
  }
}

static void MX_ADC1_Init(void)
{

  ADC_MultiModeTypeDef multimode = {0};
  ADC_ChannelConfTypeDef sConfig = {0};

  /** Common config
  */
  hadc1.Instance = ADC1;
  hadc1.Init.ClockPrescaler = ADC_CLOCK_ASYNC_DIV1;
  hadc1.Init.Resolution = ADC_RESOLUTION_16B;
  hadc1.Init.ScanConvMode = ADC_SCAN_DISABLE;
  hadc1.Init.EOCSelection = ADC_EOC_SINGLE_CONV;
  hadc1.Init.LowPowerAutoWait = DISABLE;
  hadc1.Init.ContinuousConvMode = DISABLE;
  hadc1.Init.NbrOfConversion = 1;
  hadc1.Init.DiscontinuousConvMode = DISABLE;
  hadc1.Init.ExternalTrigConv = ADC_SOFTWARE_START;
  hadc1.Init.ExternalTrigConvEdge = ADC_EXTERNALTRIGCONVEDGE_NONE;
  hadc1.Init.ConversionDataManagement = ADC_CONVERSIONDATA_DR;
  hadc1.Init.Overrun = ADC_OVR_DATA_PRESERVED;
  hadc1.Init.LeftBitShift = ADC_LEFTBITSHIFT_NONE;
  hadc1.Init.OversamplingMode = DISABLE;
  if (HAL_ADC_Init(&hadc1) != HAL_OK)
  {
    Error_Handler();
  }

  /** Configure the ADC multi-mode
  */
  multimode.Mode = ADC_MODE_INDEPENDENT;
  if (HAL_ADCEx_MultiModeConfigChannel(&hadc1, &multimode) != HAL_OK)
  {
    Error_Handler();
  }

  /** Configure Regular Channel
  */
  sConfig.Channel = ADC_CHANNEL_4;
  sConfig.Rank = ADC_REGULAR_RANK_1;
  sConfig.SamplingTime = ADC_SAMPLETIME_1CYCLE_5;
  sConfig.SingleDiff = ADC_SINGLE_ENDED;
  sConfig.OffsetNumber = ADC_OFFSET_NONE;
  sConfig.Offset = 0;
  sConfig.OffsetSignedSaturation = DISABLE;
  if (HAL_ADC_ConfigChannel(&hadc1, &sConfig) != HAL_OK)
  {
    Error_Handler();
  }

}

static void MX_ADC2_Init(void)
{

  ADC_ChannelConfTypeDef sConfig = {0};

  /** Common config
  */
  hadc2.Instance = ADC2;
  hadc2.Init.ClockPrescaler = ADC_CLOCK_ASYNC_DIV1;
  hadc2.Init.Resolution = ADC_RESOLUTION_16B;
  hadc2.Init.ScanConvMode = ADC_SCAN_DISABLE;
  hadc2.Init.EOCSelection = ADC_EOC_SINGLE_CONV;
  hadc2.Init.LowPowerAutoWait = DISABLE;
  hadc2.Init.ContinuousConvMode = DISABLE;
  hadc2.Init.NbrOfConversion = 1;
  hadc2.Init.DiscontinuousConvMode = DISABLE;
  hadc2.Init.ExternalTrigConv = ADC_SOFTWARE_START;
  hadc2.Init.ExternalTrigConvEdge = ADC_EXTERNALTRIGCONVEDGE_NONE;
  hadc2.Init.ConversionDataManagement = ADC_CONVERSIONDATA_DR;
  hadc2.Init.Overrun = ADC_OVR_DATA_PRESERVED;
  hadc2.Init.LeftBitShift = ADC_LEFTBITSHIFT_NONE;
  hadc2.Init.OversamplingMode = DISABLE;
  if (HAL_ADC_Init(&hadc2) != HAL_OK)
  {
    Error_Handler();
  }

  /** Configure Regular Channel
  */
  sConfig.Channel = ADC_CHANNEL_8;
  sConfig.Rank = ADC_REGULAR_RANK_1;
  sConfig.SamplingTime = ADC_SAMPLETIME_1CYCLE_5;
  sConfig.SingleDiff = ADC_SINGLE_ENDED;
  sConfig.OffsetNumber = ADC_OFFSET_NONE;
  sConfig.Offset = 0;
  sConfig.OffsetSignedSaturation = DISABLE;
  if (HAL_ADC_ConfigChannel(&hadc2, &sConfig) != HAL_OK)
  {
    Error_Handler();
  }

}

static void MX_DAC1_Init(void)
{

  DAC_ChannelConfTypeDef sConfig = {0};

  /** DAC Initialization
  */
  hdac1.Instance = DAC1;
  if (HAL_DAC_Init(&hdac1) != HAL_OK)
  {
    Error_Handler();
  }

  /** DAC channel OUT1 config
  */
  sConfig.DAC_SampleAndHold = DAC_SAMPLEANDHOLD_DISABLE;
  sConfig.DAC_Trigger = DAC_TRIGGER_NONE;
  sConfig.DAC_OutputBuffer = DAC_OUTPUTBUFFER_ENABLE;
  sConfig.DAC_ConnectOnChipPeripheral = DAC_CHIPCONNECT_DISABLE;
  sConfig.DAC_UserTrimming = DAC_TRIMMING_FACTORY;
  if (HAL_DAC_ConfigChannel(&hdac1, &sConfig, DAC_CHANNEL_1) != HAL_OK)
  {
    Error_Handler();
  }

  /** DAC channel OUT2 config
  */
  if (HAL_DAC_ConfigChannel(&hdac1, &sConfig, DAC_CHANNEL_2) != HAL_OK)
  {
    Error_Handler();
  }

}

static void MX_I2C1_Init(void)
{

  hi2c1.Instance = I2C1;
  hi2c1.Init.Timing = 0x10707DBC;
  hi2c1.Init.OwnAddress1 = 0;
  hi2c1.Init.AddressingMode = I2C_ADDRESSINGMODE_7BIT;
  hi2c1.Init.DualAddressMode = I2C_DUALADDRESS_DISABLE;
  hi2c1.Init.OwnAddress2 = 0;
  hi2c1.Init.OwnAddress2Masks = I2C_OA2_NOMASK;
  hi2c1.Init.GeneralCallMode = I2C_GENERALCALL_DISABLE;
  hi2c1.Init.NoStretchMode = I2C_NOSTRETCH_DISABLE;
  if (HAL_I2C_Init(&hi2c1) != HAL_OK)
  {
    Error_Handler();
  }

  /** Configure Analogue filter
  */
  if (HAL_I2CEx_ConfigAnalogFilter(&hi2c1, I2C_ANALOGFILTER_ENABLE) != HAL_OK)
  {
    Error_Handler();
  }

  /** Configure Digital filter
  */
  if (HAL_I2CEx_ConfigDigitalFilter(&hi2c1, 0) != HAL_OK)
  {
    Error_Handler();
  }

}

static void MX_I2C2_Init(void)
{

  hi2c2.Instance = I2C2;
  hi2c2.Init.Timing = 0x10707DBC;
  hi2c2.Init.OwnAddress1 = 0;
  hi2c2.Init.AddressingMode = I2C_ADDRESSINGMODE_7BIT;
  hi2c2.Init.DualAddressMode = I2C_DUALADDRESS_DISABLE;
  hi2c2.Init.OwnAddress2 = 0;
  hi2c2.Init.OwnAddress2Masks = I2C_OA2_NOMASK;
  hi2c2.Init.GeneralCallMode = I2C_GENERALCALL_DISABLE;
  hi2c2.Init.NoStretchMode = I2C_NOSTRETCH_DISABLE;
  if (HAL_I2C_Init(&hi2c2) != HAL_OK)
  {
    Error_Handler();
  }

  /** Configure Analogue filter
  */
  if (HAL_I2CEx_ConfigAnalogFilter(&hi2c2, I2C_ANALOGFILTER_ENABLE) != HAL_OK)
  {
    Error_Handler();
  }

  /** Configure Digital filter
  */
  if (HAL_I2CEx_ConfigDigitalFilter(&hi2c2, 0) != HAL_OK)
  {
    Error_Handler();
  }

}

static void MX_SAI1_Init(void)
{

  hsai_BlockA1.Instance = SAI1_Block_A;
  hsai_BlockA1.Init.AudioMode = SAI_MODEMASTER_TX;
  hsai_BlockA1.Init.Synchro = SAI_ASYNCHRONOUS;
  hsai_BlockA1.Init.OutputDrive = SAI_OUTPUTDRIVE_DISABLE;
  hsai_BlockA1.Init.NoDivider = SAI_MASTERDIVIDER_ENABLE;
  hsai_BlockA1.Init.FIFOThreshold = SAI_FIFOTHRESHOLD_EMPTY;
  hsai_BlockA1.Init.AudioFrequency = SAI_AUDIO_FREQUENCY_48K;
  hsai_BlockA1.Init.SynchroExt = SAI_SYNCEXT_DISABLE;
  hsai_BlockA1.Init.MonoStereoMode = SAI_STEREOMODE;
  hsai_BlockA1.Init.CompandingMode = SAI_NOCOMPANDING;
  hsai_BlockA1.Init.TriState = SAI_OUTPUT_NOTRELEASED;
  if (HAL_SAI_InitProtocol(&hsai_BlockA1, SAI_I2S_STANDARD, SAI_PROTOCOL_DATASIZE_16BIT, 2) != HAL_OK)
  {
    Error_Handler();
  }
  hsai_BlockB1.Instance = SAI1_Block_B;
  hsai_BlockB1.Init.AudioMode = SAI_MODESLAVE_RX;
  hsai_BlockB1.Init.Synchro = SAI_SYNCHRONOUS;
  hsai_BlockB1.Init.OutputDrive = SAI_OUTPUTDRIVE_DISABLE;
  hsai_BlockB1.Init.FIFOThreshold = SAI_FIFOTHRESHOLD_EMPTY;
  hsai_BlockB1.Init.SynchroExt = SAI_SYNCEXT_DISABLE;
  hsai_BlockB1.Init.MonoStereoMode = SAI_STEREOMODE;
  hsai_BlockB1.Init.CompandingMode = SAI_NOCOMPANDING;
  hsai_BlockB1.Init.TriState = SAI_OUTPUT_NOTRELEASED;
  if (HAL_SAI_InitProtocol(&hsai_BlockB1, SAI_I2S_STANDARD, SAI_PROTOCOL_DATASIZE_16BIT, 2) != HAL_OK)
  {
    Error_Handler();
  }

}

static void MX_SPI2_Init(void)
{

  /* SPI2 parameter configuration*/
  hspi2.Instance = SPI2;
  hspi2.Init.Mode = SPI_MODE_MASTER;
  hspi2.Init.Direction = SPI_DIRECTION_2LINES;
  hspi2.Init.DataSize = SPI_DATASIZE_4BIT;
  hspi2.Init.CLKPolarity = SPI_POLARITY_LOW;
  hspi2.Init.CLKPhase = SPI_PHASE_1EDGE;
  hspi2.Init.NSS = SPI_NSS_HARD_OUTPUT;
  hspi2.Init.BaudRatePrescaler = SPI_BAUDRATEPRESCALER_2;
  hspi2.Init.FirstBit = SPI_FIRSTBIT_MSB;
  hspi2.Init.TIMode = SPI_TIMODE_DISABLE;
  hspi2.Init.CRCCalculation = SPI_CRCCALCULATION_DISABLE;
  hspi2.Init.CRCPolynomial = 0x0;
  hspi2.Init.NSSPMode = SPI_NSS_PULSE_ENABLE;
  hspi2.Init.NSSPolarity = SPI_NSS_POLARITY_LOW;
  hspi2.Init.FifoThreshold = SPI_FIFO_THRESHOLD_01DATA;
  hspi2.Init.TxCRCInitializationPattern = SPI_CRC_INITIALIZATION_ALL_ZERO_PATTERN;
  hspi2.Init.RxCRCInitializationPattern = SPI_CRC_INITIALIZATION_ALL_ZERO_PATTERN;
  hspi2.Init.MasterSSIdleness = SPI_MASTER_SS_IDLENESS_00CYCLE;
  hspi2.Init.MasterInterDataIdleness = SPI_MASTER_INTERDATA_IDLENESS_00CYCLE;
  hspi2.Init.MasterReceiverAutoSusp = SPI_MASTER_RX_AUTOSUSP_DISABLE;
  hspi2.Init.MasterKeepIOState = SPI_MASTER_KEEP_IO_STATE_DISABLE;
  hspi2.Init.IOSwap = SPI_IO_SWAP_DISABLE;
  if (HAL_SPI_Init(&hspi2) != HAL_OK)
  {
    Error_Handler();
  }

}

static void MX_SPI3_Init(void)
{

  /* SPI3 parameter configuration*/
  hspi3.Instance = SPI3;
  hspi3.Init.Mode = SPI_MODE_MASTER;
  hspi3.Init.Direction = SPI_DIRECTION_2LINES_TXONLY;
  hspi3.Init.DataSize = SPI_DATASIZE_8BIT;
  hspi3.Init.CLKPolarity = SPI_POLARITY_LOW;
  hspi3.Init.CLKPhase = SPI_PHASE_1EDGE;
  hspi3.Init.NSS = SPI_NSS_HARD_OUTPUT;
  hspi3.Init.BaudRatePrescaler = SPI_BAUDRATEPRESCALER_4;
  hspi3.Init.FirstBit = SPI_FIRSTBIT_MSB;
  hspi3.Init.TIMode = SPI_TIMODE_DISABLE;
  hspi3.Init.CRCCalculation = SPI_CRCCALCULATION_DISABLE;
  hspi3.Init.CRCPolynomial = 0x0;
  hspi3.Init.NSSPMode = SPI_NSS_PULSE_ENABLE;
  hspi3.Init.NSSPolarity = SPI_NSS_POLARITY_LOW;
  hspi3.Init.FifoThreshold = SPI_FIFO_THRESHOLD_01DATA;
  hspi3.Init.TxCRCInitializationPattern = SPI_CRC_INITIALIZATION_ALL_ZERO_PATTERN;
  hspi3.Init.RxCRCInitializationPattern = SPI_CRC_INITIALIZATION_ALL_ZERO_PATTERN;
  hspi3.Init.MasterSSIdleness = SPI_MASTER_SS_IDLENESS_00CYCLE;
  hspi3.Init.MasterInterDataIdleness = SPI_MASTER_INTERDATA_IDLENESS_00CYCLE;
  hspi3.Init.MasterReceiverAutoSusp = SPI_MASTER_RX_AUTOSUSP_DISABLE;
  hspi3.Init.MasterKeepIOState = SPI_MASTER_KEEP_IO_STATE_ENABLE;
  hspi3.Init.IOSwap = SPI_IO_SWAP_DISABLE;
  if (HAL_SPI_Init(&hspi3) != HAL_OK)
  {
    Error_Handler();
  }

}

static void MX_SPI4_Init(void)
{

  /* SPI4 parameter configuration*/
  hspi4.Instance = SPI4;
  hspi4.Init.Mode = SPI_MODE_MASTER;
  hspi4.Init.Direction = SPI_DIRECTION_2LINES;
  hspi4.Init.DataSize = SPI_DATASIZE_4BIT;
  hspi4.Init.CLKPolarity = SPI_POLARITY_LOW;
  hspi4.Init.CLKPhase = SPI_PHASE_1EDGE;
  hspi4.Init.NSS = SPI_NSS_HARD_OUTPUT;
  hspi4.Init.BaudRatePrescaler = SPI_BAUDRATEPRESCALER_2;
  hspi4.Init.FirstBit = SPI_FIRSTBIT_MSB;
  hspi4.Init.TIMode = SPI_TIMODE_DISABLE;
  hspi4.Init.CRCCalculation = SPI_CRCCALCULATION_DISABLE;
  hspi4.Init.CRCPolynomial = 0x0;
  hspi4.Init.NSSPMode = SPI_NSS_PULSE_ENABLE;
  hspi4.Init.NSSPolarity = SPI_NSS_POLARITY_LOW;
  hspi4.Init.FifoThreshold = SPI_FIFO_THRESHOLD_01DATA;
  hspi4.Init.TxCRCInitializationPattern = SPI_CRC_INITIALIZATION_ALL_ZERO_PATTERN;
  hspi4.Init.RxCRCInitializationPattern = SPI_CRC_INITIALIZATION_ALL_ZERO_PATTERN;
  hspi4.Init.MasterSSIdleness = SPI_MASTER_SS_IDLENESS_00CYCLE;
  hspi4.Init.MasterInterDataIdleness = SPI_MASTER_INTERDATA_IDLENESS_00CYCLE;
  hspi4.Init.MasterReceiverAutoSusp = SPI_MASTER_RX_AUTOSUSP_DISABLE;
  hspi4.Init.MasterKeepIOState = SPI_MASTER_KEEP_IO_STATE_DISABLE;
  hspi4.Init.IOSwap = SPI_IO_SWAP_DISABLE;
  if (HAL_SPI_Init(&hspi4) != HAL_OK)
  {
    Error_Handler();
  }

}

static void MX_TIM1_Init(void)
{

  TIM_Encoder_InitTypeDef sConfig = {0};
  TIM_MasterConfigTypeDef sMasterConfig = {0};

  htim1.Instance = TIM1;
  htim1.Init.Prescaler = 0;
  htim1.Init.CounterMode = TIM_COUNTERMODE_UP;
  htim1.Init.Period = 65535;
  htim1.Init.ClockDivision = TIM_CLOCKDIVISION_DIV1;
  htim1.Init.RepetitionCounter = 0;
  htim1.Init.AutoReloadPreload = TIM_AUTORELOAD_PRELOAD_DISABLE;
  sConfig.EncoderMode = TIM_ENCODERMODE_TI1;
  sConfig.IC1Polarity = TIM_ICPOLARITY_RISING;
  sConfig.IC1Selection = TIM_ICSELECTION_DIRECTTI;
  sConfig.IC1Prescaler = TIM_ICPSC_DIV1;
  sConfig.IC1Filter = 7;
  sConfig.IC2Polarity = TIM_ICPOLARITY_RISING;
  sConfig.IC2Selection = TIM_ICSELECTION_DIRECTTI;
  sConfig.IC2Prescaler = TIM_ICPSC_DIV1;
  sConfig.IC2Filter = 7;
  if (HAL_TIM_Encoder_Init(&htim1, &sConfig) != HAL_OK)
  {
    Error_Handler();
  }
  sMasterConfig.MasterOutputTrigger = TIM_TRGO_RESET;
  sMasterConfig.MasterOutputTrigger2 = TIM_TRGO2_RESET;
  sMasterConfig.MasterSlaveMode = TIM_MASTERSLAVEMODE_DISABLE;
  if (HAL_TIMEx_MasterConfigSynchronization(&htim1, &sMasterConfig) != HAL_OK)
  {
    Error_Handler();
  }

}

static void MX_TIM2_Init(void)
{

  TIM_Encoder_InitTypeDef sConfig = {0};
  TIM_MasterConfigTypeDef sMasterConfig = {0};

  htim2.Instance = TIM2;
  htim2.Init.Prescaler = 0;
  htim2.Init.CounterMode = TIM_COUNTERMODE_UP;
  htim2.Init.Period = 4294967295;
  htim2.Init.ClockDivision = TIM_CLOCKDIVISION_DIV1;
  htim2.Init.AutoReloadPreload = TIM_AUTORELOAD_PRELOAD_DISABLE;
  sConfig.EncoderMode = TIM_ENCODERMODE_TI1;
  sConfig.IC1Polarity = TIM_ICPOLARITY_RISING;
  sConfig.IC1Selection = TIM_ICSELECTION_DIRECTTI;
  sConfig.IC1Prescaler = TIM_ICPSC_DIV1;
  sConfig.IC1Filter = 7;
  sConfig.IC2Polarity = TIM_ICPOLARITY_RISING;
  sConfig.IC2Selection = TIM_ICSELECTION_DIRECTTI;
  sConfig.IC2Prescaler = TIM_ICPSC_DIV1;
  sConfig.IC2Filter = 7;
  if (HAL_TIM_Encoder_Init(&htim2, &sConfig) != HAL_OK)
  {
    Error_Handler();
  }
  sMasterConfig.MasterOutputTrigger = TIM_TRGO_RESET;
  sMasterConfig.MasterSlaveMode = TIM_MASTERSLAVEMODE_DISABLE;
  if (HAL_TIMEx_MasterConfigSynchronization(&htim2, &sMasterConfig) != HAL_OK)
  {
    Error_Handler();
  }

}

static void MX_TIM3_Init(void)
{

  TIM_MasterConfigTypeDef sMasterConfig = {0};
  TIM_OC_InitTypeDef sConfigOC = {0};

  htim3.Instance = TIM3;
  htim3.Init.Prescaler = 7199;
  htim3.Init.CounterMode = TIM_COUNTERMODE_UP;
  htim3.Init.Period = 499;
  htim3.Init.ClockDivision = TIM_CLOCKDIVISION_DIV1;
  htim3.Init.AutoReloadPreload = TIM_AUTORELOAD_PRELOAD_DISABLE;
  if (HAL_TIM_PWM_Init(&htim3) != HAL_OK)
  {
    Error_Handler();
  }
  sMasterConfig.MasterOutputTrigger = TIM_TRGO_RESET;
  sMasterConfig.MasterSlaveMode = TIM_MASTERSLAVEMODE_DISABLE;
  if (HAL_TIMEx_MasterConfigSynchronization(&htim3, &sMasterConfig) != HAL_OK)
  {
    Error_Handler();
  }
  sConfigOC.OCMode = TIM_OCMODE_PWM1;
  sConfigOC.Pulse = 0;
  sConfigOC.OCPolarity = TIM_OCPOLARITY_HIGH;
  sConfigOC.OCFastMode = TIM_OCFAST_DISABLE;
  if (HAL_TIM_PWM_ConfigChannel(&htim3, &sConfigOC, TIM_CHANNEL_1) != HAL_OK)
  {
    Error_Handler();
  }
  if (HAL_TIM_PWM_ConfigChannel(&htim3, &sConfigOC, TIM_CHANNEL_2) != HAL_OK)
  {
    Error_Handler();
  }
  if (HAL_TIM_PWM_ConfigChannel(&htim3, &sConfigOC, TIM_CHANNEL_3) != HAL_OK)
  {
    Error_Handler();
  }
  if (HAL_TIM_PWM_ConfigChannel(&htim3, &sConfigOC, TIM_CHANNEL_4) != HAL_OK)
  {
    Error_Handler();
  }
  HAL_TIM_MspPostInit(&htim3);

}

static void MX_TIM4_Init(void)
{

  TIM_MasterConfigTypeDef sMasterConfig = {0};
  TIM_OC_InitTypeDef sConfigOC = {0};

  htim4.Instance = TIM4;
  htim4.Init.Prescaler = 7199;
  htim4.Init.CounterMode = TIM_COUNTERMODE_UP;
  htim4.Init.Period = 499;
  htim4.Init.ClockDivision = TIM_CLOCKDIVISION_DIV1;
  htim4.Init.AutoReloadPreload = TIM_AUTORELOAD_PRELOAD_DISABLE;
  if (HAL_TIM_PWM_Init(&htim4) != HAL_OK)
  {
    Error_Handler();
  }
  sMasterConfig.MasterOutputTrigger = TIM_TRGO_RESET;
  sMasterConfig.MasterSlaveMode = TIM_MASTERSLAVEMODE_DISABLE;
  if (HAL_TIMEx_MasterConfigSynchronization(&htim4, &sMasterConfig) != HAL_OK)
  {
    Error_Handler();
  }
  sConfigOC.OCMode = TIM_OCMODE_PWM1;
  sConfigOC.Pulse = 0;
  sConfigOC.OCPolarity = TIM_OCPOLARITY_HIGH;
  sConfigOC.OCFastMode = TIM_OCFAST_DISABLE;
  if (HAL_TIM_PWM_ConfigChannel(&htim4, &sConfigOC, TIM_CHANNEL_1) != HAL_OK)
  {
    Error_Handler();
  }
  if (HAL_TIM_PWM_ConfigChannel(&htim4, &sConfigOC, TIM_CHANNEL_2) != HAL_OK)
  {
    Error_Handler();
  }
  if (HAL_TIM_PWM_ConfigChannel(&htim4, &sConfigOC, TIM_CHANNEL_3) != HAL_OK)
  {
    Error_Handler();
  }
  if (HAL_TIM_PWM_ConfigChannel(&htim4, &sConfigOC, TIM_CHANNEL_4) != HAL_OK)
  {
    Error_Handler();
  }
  HAL_TIM_MspPostInit(&htim4);

}

static void MX_TIM8_Init(void)
{

  TIM_MasterConfigTypeDef sMasterConfig = {0};
  TIM_OC_InitTypeDef sConfigOC = {0};
  TIM_BreakDeadTimeConfigTypeDef sBreakDeadTimeConfig = {0};

  htim8.Instance = TIM8;
  htim8.Init.Prescaler = 7199;
  htim8.Init.CounterMode = TIM_COUNTERMODE_UP;
  htim8.Init.Period = 499;
  htim8.Init.ClockDivision = TIM_CLOCKDIVISION_DIV1;
  htim8.Init.RepetitionCounter = 0;
  htim8.Init.AutoReloadPreload = TIM_AUTORELOAD_PRELOAD_DISABLE;
  if (HAL_TIM_PWM_Init(&htim8) != HAL_OK)
  {
    Error_Handler();
  }
  sMasterConfig.MasterOutputTrigger = TIM_TRGO_RESET;
  sMasterConfig.MasterOutputTrigger2 = TIM_TRGO2_RESET;
  sMasterConfig.MasterSlaveMode = TIM_MASTERSLAVEMODE_DISABLE;
  if (HAL_TIMEx_MasterConfigSynchronization(&htim8, &sMasterConfig) != HAL_OK)
  {
    Error_Handler();
  }
  sConfigOC.OCMode = TIM_OCMODE_PWM1;
  sConfigOC.Pulse = 0;
  sConfigOC.OCPolarity = TIM_OCPOLARITY_HIGH;
  sConfigOC.OCNPolarity = TIM_OCNPOLARITY_HIGH;
  sConfigOC.OCFastMode = TIM_OCFAST_DISABLE;
  sConfigOC.OCIdleState = TIM_OCIDLESTATE_RESET;
  sConfigOC.OCNIdleState = TIM_OCNIDLESTATE_RESET;
  if (HAL_TIM_PWM_ConfigChannel(&htim8, &sConfigOC, TIM_CHANNEL_1) != HAL_OK)
  {
    Error_Handler();
  }
  if (HAL_TIM_PWM_ConfigChannel(&htim8, &sConfigOC, TIM_CHANNEL_2) != HAL_OK)
  {
    Error_Handler();
  }
  if (HAL_TIM_PWM_ConfigChannel(&htim8, &sConfigOC, TIM_CHANNEL_3) != HAL_OK)
  {
    Error_Handler();
  }
  if (HAL_TIM_PWM_ConfigChannel(&htim8, &sConfigOC, TIM_CHANNEL_4) != HAL_OK)
  {
    Error_Handler();
  }
  sBreakDeadTimeConfig.OffStateRunMode = TIM_OSSR_DISABLE;
  sBreakDeadTimeConfig.OffStateIDLEMode = TIM_OSSI_DISABLE;
  sBreakDeadTimeConfig.LockLevel = TIM_LOCKLEVEL_OFF;
  sBreakDeadTimeConfig.DeadTime = 0;
  sBreakDeadTimeConfig.BreakState = TIM_BREAK_DISABLE;
  sBreakDeadTimeConfig.BreakPolarity = TIM_BREAKPOLARITY_HIGH;
  sBreakDeadTimeConfig.BreakFilter = 0;
  sBreakDeadTimeConfig.Break2State = TIM_BREAK2_DISABLE;
  sBreakDeadTimeConfig.Break2Polarity = TIM_BREAK2POLARITY_HIGH;
  sBreakDeadTimeConfig.Break2Filter = 0;
  sBreakDeadTimeConfig.AutomaticOutput = TIM_AUTOMATICOUTPUT_DISABLE;
  if (HAL_TIMEx_ConfigBreakDeadTime(&htim8, &sBreakDeadTimeConfig) != HAL_OK)
  {
    Error_Handler();
  }
  HAL_TIM_MspPostInit(&htim8);

}

static void MX_TIM13_Init(void)
{

  TIM_OC_InitTypeDef sConfigOC = {0};

  htim13.Instance = TIM13;
  htim13.Init.Prescaler = 7199;
  htim13.Init.CounterMode = TIM_COUNTERMODE_UP;
  htim13.Init.Period = 499;
  htim13.Init.ClockDivision = TIM_CLOCKDIVISION_DIV1;
  htim13.Init.AutoReloadPreload = TIM_AUTORELOAD_PRELOAD_DISABLE;
  if (HAL_TIM_Base_Init(&htim13) != HAL_OK)
  {
    Error_Handler();
  }
  if (HAL_TIM_PWM_Init(&htim13) != HAL_OK)
  {
    Error_Handler();
  }
  sConfigOC.OCMode = TIM_OCMODE_PWM1;
  sConfigOC.Pulse = 0;
  sConfigOC.OCPolarity = TIM_OCPOLARITY_HIGH;
  sConfigOC.OCFastMode = TIM_OCFAST_DISABLE;
  if (HAL_TIM_PWM_ConfigChannel(&htim13, &sConfigOC, TIM_CHANNEL_1) != HAL_OK)
  {
    Error_Handler();
  }
  HAL_TIM_MspPostInit(&htim13);

}

static void MX_TIM14_Init(void)
{

  TIM_OC_InitTypeDef sConfigOC = {0};

  htim14.Instance = TIM14;
  htim14.Init.Prescaler = 7199;
  htim14.Init.CounterMode = TIM_COUNTERMODE_UP;
  htim14.Init.Period = 499;
  htim14.Init.ClockDivision = TIM_CLOCKDIVISION_DIV1;
  htim14.Init.AutoReloadPreload = TIM_AUTORELOAD_PRELOAD_DISABLE;
  if (HAL_TIM_Base_Init(&htim14) != HAL_OK)
  {
    Error_Handler();
  }
  if (HAL_TIM_PWM_Init(&htim14) != HAL_OK)
  {
    Error_Handler();
  }
  sConfigOC.OCMode = TIM_OCMODE_PWM1;
  sConfigOC.Pulse = 0;
  sConfigOC.OCPolarity = TIM_OCPOLARITY_HIGH;
  sConfigOC.OCFastMode = TIM_OCFAST_DISABLE;
  if (HAL_TIM_PWM_ConfigChannel(&htim14, &sConfigOC, TIM_CHANNEL_1) != HAL_OK)
  {
    Error_Handler();
  }
  HAL_TIM_MspPostInit(&htim14);

}

static void MX_TIM15_Init(void)
{

  TIM_MasterConfigTypeDef sMasterConfig = {0};
  TIM_OC_InitTypeDef sConfigOC = {0};
  TIM_BreakDeadTimeConfigTypeDef sBreakDeadTimeConfig = {0};

  htim15.Instance = TIM15;
  htim15.Init.Prescaler = 7199;
  htim15.Init.CounterMode = TIM_COUNTERMODE_UP;
  htim15.Init.Period = 499;
  htim15.Init.ClockDivision = TIM_CLOCKDIVISION_DIV1;
  htim15.Init.RepetitionCounter = 0;
  htim15.Init.AutoReloadPreload = TIM_AUTORELOAD_PRELOAD_DISABLE;
  if (HAL_TIM_PWM_Init(&htim15) != HAL_OK)
  {
    Error_Handler();
  }
  sMasterConfig.MasterOutputTrigger = TIM_TRGO_RESET;
  sMasterConfig.MasterSlaveMode = TIM_MASTERSLAVEMODE_DISABLE;
  if (HAL_TIMEx_MasterConfigSynchronization(&htim15, &sMasterConfig) != HAL_OK)
  {
    Error_Handler();
  }
  sConfigOC.OCMode = TIM_OCMODE_PWM1;
  sConfigOC.Pulse = 0;
  sConfigOC.OCPolarity = TIM_OCPOLARITY_HIGH;
  sConfigOC.OCNPolarity = TIM_OCNPOLARITY_HIGH;
  sConfigOC.OCFastMode = TIM_OCFAST_DISABLE;
  sConfigOC.OCIdleState = TIM_OCIDLESTATE_RESET;
  sConfigOC.OCNIdleState = TIM_OCNIDLESTATE_RESET;
  if (HAL_TIM_PWM_ConfigChannel(&htim15, &sConfigOC, TIM_CHANNEL_1) != HAL_OK)
  {
    Error_Handler();
  }
  sBreakDeadTimeConfig.OffStateRunMode = TIM_OSSR_DISABLE;
  sBreakDeadTimeConfig.OffStateIDLEMode = TIM_OSSI_DISABLE;
  sBreakDeadTimeConfig.LockLevel = TIM_LOCKLEVEL_OFF;
  sBreakDeadTimeConfig.DeadTime = 0;
  sBreakDeadTimeConfig.BreakState = TIM_BREAK_DISABLE;
  sBreakDeadTimeConfig.BreakPolarity = TIM_BREAKPOLARITY_HIGH;
  sBreakDeadTimeConfig.BreakFilter = 0;
  sBreakDeadTimeConfig.AutomaticOutput = TIM_AUTOMATICOUTPUT_DISABLE;
  if (HAL_TIMEx_ConfigBreakDeadTime(&htim15, &sBreakDeadTimeConfig) != HAL_OK)
  {
    Error_Handler();
  }
  HAL_TIM_MspPostInit(&htim15);

}

static void MX_TIM16_Init(void)
{

  TIM_OC_InitTypeDef sConfigOC = {0};
  TIM_BreakDeadTimeConfigTypeDef sBreakDeadTimeConfig = {0};

  htim16.Instance = TIM16;
  htim16.Init.Prescaler = 7199;
  htim16.Init.CounterMode = TIM_COUNTERMODE_UP;
  htim16.Init.Period = 499;
  htim16.Init.ClockDivision = TIM_CLOCKDIVISION_DIV1;
  htim16.Init.RepetitionCounter = 0;
  htim16.Init.AutoReloadPreload = TIM_AUTORELOAD_PRELOAD_DISABLE;
  if (HAL_TIM_Base_Init(&htim16) != HAL_OK)
  {
    Error_Handler();
  }
  if (HAL_TIM_PWM_Init(&htim16) != HAL_OK)
  {
    Error_Handler();
  }
  sConfigOC.OCMode = TIM_OCMODE_PWM1;
  sConfigOC.Pulse = 250;
  sConfigOC.OCPolarity = TIM_OCPOLARITY_HIGH;
  sConfigOC.OCNPolarity = TIM_OCNPOLARITY_HIGH;
  sConfigOC.OCFastMode = TIM_OCFAST_DISABLE;
  sConfigOC.OCIdleState = TIM_OCIDLESTATE_SET;
  sConfigOC.OCNIdleState = TIM_OCNIDLESTATE_RESET;
  if (HAL_TIM_PWM_ConfigChannel(&htim16, &sConfigOC, TIM_CHANNEL_1) != HAL_OK)
  {
    Error_Handler();
  }
  sBreakDeadTimeConfig.OffStateRunMode = TIM_OSSR_DISABLE;
  sBreakDeadTimeConfig.OffStateIDLEMode = TIM_OSSI_DISABLE;
  sBreakDeadTimeConfig.LockLevel = TIM_LOCKLEVEL_OFF;
  sBreakDeadTimeConfig.DeadTime = 0;
  sBreakDeadTimeConfig.BreakState = TIM_BREAK_DISABLE;
  sBreakDeadTimeConfig.BreakPolarity = TIM_BREAKPOLARITY_HIGH;
  sBreakDeadTimeConfig.BreakFilter = 0;
  sBreakDeadTimeConfig.AutomaticOutput = TIM_AUTOMATICOUTPUT_DISABLE;
  if (HAL_TIMEx_ConfigBreakDeadTime(&htim16, &sBreakDeadTimeConfig) != HAL_OK)
  {
    Error_Handler();
  }
  HAL_TIM_MspPostInit(&htim16);

}

static void MX_TIM17_Init(void)
{

  TIM_OC_InitTypeDef sConfigOC = {0};
  TIM_BreakDeadTimeConfigTypeDef sBreakDeadTimeConfig = {0};

  htim17.Instance = TIM17;
  htim17.Init.Prescaler = 0;
  htim17.Init.CounterMode = TIM_COUNTERMODE_UP;
  htim17.Init.Period = 65535;
  htim17.Init.ClockDivision = TIM_CLOCKDIVISION_DIV1;
  htim17.Init.RepetitionCounter = 0;
  htim17.Init.AutoReloadPreload = TIM_AUTORELOAD_PRELOAD_DISABLE;
  if (HAL_TIM_Base_Init(&htim17) != HAL_OK)
  {
    Error_Handler();
  }
  if (HAL_TIM_PWM_Init(&htim17) != HAL_OK)
  {
    Error_Handler();
  }
  sConfigOC.OCMode = TIM_OCMODE_PWM1;
  sConfigOC.Pulse = 0;
  sConfigOC.OCPolarity = TIM_OCPOLARITY_HIGH;
  sConfigOC.OCNPolarity = TIM_OCNPOLARITY_HIGH;
  sConfigOC.OCFastMode = TIM_OCFAST_DISABLE;
  sConfigOC.OCIdleState = TIM_OCIDLESTATE_RESET;
  sConfigOC.OCNIdleState = TIM_OCNIDLESTATE_RESET;
  if (HAL_TIM_PWM_ConfigChannel(&htim17, &sConfigOC, TIM_CHANNEL_1) != HAL_OK)
  {
    Error_Handler();
  }
  sBreakDeadTimeConfig.OffStateRunMode = TIM_OSSR_DISABLE;
  sBreakDeadTimeConfig.OffStateIDLEMode = TIM_OSSI_DISABLE;
  sBreakDeadTimeConfig.LockLevel = TIM_LOCKLEVEL_OFF;
  sBreakDeadTimeConfig.DeadTime = 0;
  sBreakDeadTimeConfig.BreakState = TIM_BREAK_DISABLE;
  sBreakDeadTimeConfig.BreakPolarity = TIM_BREAKPOLARITY_HIGH;
  sBreakDeadTimeConfig.BreakFilter = 0;
  sBreakDeadTimeConfig.AutomaticOutput = TIM_AUTOMATICOUTPUT_DISABLE;
  if (HAL_TIMEx_ConfigBreakDeadTime(&htim17, &sBreakDeadTimeConfig) != HAL_OK)
  {
    Error_Handler();
  }
  HAL_TIM_MspPostInit(&htim17);

}

static void MX_UART7_Init(void)
{

  huart7.Instance = UART7;
  huart7.Init.BaudRate = 115200;
  huart7.Init.WordLength = UART_WORDLENGTH_8B;
  huart7.Init.StopBits = UART_STOPBITS_1;
  huart7.Init.Parity = UART_PARITY_NONE;
  huart7.Init.Mode = UART_MODE_TX_RX;
  huart7.Init.HwFlowCtl = UART_HWCONTROL_NONE;
  huart7.Init.OverSampling = UART_OVERSAMPLING_16;
  huart7.Init.OneBitSampling = UART_ONE_BIT_SAMPLE_DISABLE;
  huart7.Init.ClockPrescaler = UART_PRESCALER_DIV1;
  huart7.AdvancedInit.AdvFeatureInit = UART_ADVFEATURE_NO_INIT;
  if (HAL_UART_Init(&huart7) != HAL_OK)
  {
    Error_Handler();
  }
  if (HAL_UARTEx_SetTxFifoThreshold(&huart7, UART_TXFIFO_THRESHOLD_1_8) != HAL_OK)
  {
    Error_Handler();
  }
  if (HAL_UARTEx_SetRxFifoThreshold(&huart7, UART_RXFIFO_THRESHOLD_1_8) != HAL_OK)
  {
    Error_Handler();
  }
  if (HAL_UARTEx_DisableFifoMode(&huart7) != HAL_OK)
  {
    Error_Handler();
  }

}

static void MX_UART8_Init(void)
{

  huart8.Instance = UART8;
  huart8.Init.BaudRate = 115200;
  huart8.Init.WordLength = UART_WORDLENGTH_8B;
  huart8.Init.StopBits = UART_STOPBITS_1;
  huart8.Init.Parity = UART_PARITY_NONE;
  huart8.Init.Mode = UART_MODE_TX_RX;
  huart8.Init.HwFlowCtl = UART_HWCONTROL_NONE;
  huart8.Init.OverSampling = UART_OVERSAMPLING_16;
  huart8.Init.OneBitSampling = UART_ONE_BIT_SAMPLE_DISABLE;
  huart8.Init.ClockPrescaler = UART_PRESCALER_DIV1;
  huart8.AdvancedInit.AdvFeatureInit = UART_ADVFEATURE_NO_INIT;
  if (HAL_UART_Init(&huart8) != HAL_OK)
  {
    Error_Handler();
  }
  if (HAL_UARTEx_SetTxFifoThreshold(&huart8, UART_TXFIFO_THRESHOLD_1_8) != HAL_OK)
  {
    Error_Handler();
  }
  if (HAL_UARTEx_SetRxFifoThreshold(&huart8, UART_RXFIFO_THRESHOLD_1_8) != HAL_OK)
  {
    Error_Handler();
  }
  if (HAL_UARTEx_DisableFifoMode(&huart8) != HAL_OK)
  {
    Error_Handler();
  }

}

static void MX_USART2_UART_Init(void)
{

  huart2.Instance = USART2;
  huart2.Init.BaudRate = 115200;
  huart2.Init.WordLength = UART_WORDLENGTH_8B;
  huart2.Init.StopBits = UART_STOPBITS_1;
  huart2.Init.Parity = UART_PARITY_NONE;
  huart2.Init.Mode = UART_MODE_TX_RX;
  huart2.Init.HwFlowCtl = UART_HWCONTROL_NONE;
  huart2.Init.OverSampling = UART_OVERSAMPLING_16;
  huart2.Init.OneBitSampling = UART_ONE_BIT_SAMPLE_DISABLE;
  huart2.Init.ClockPrescaler = UART_PRESCALER_DIV1;
  huart2.AdvancedInit.AdvFeatureInit = UART_ADVFEATURE_NO_INIT;
  if (HAL_UART_Init(&huart2) != HAL_OK)
  {
    Error_Handler();
  }
  if (HAL_UARTEx_SetTxFifoThreshold(&huart2, UART_TXFIFO_THRESHOLD_1_8) != HAL_OK)
  {
    Error_Handler();
  }
  if (HAL_UARTEx_SetRxFifoThreshold(&huart2, UART_RXFIFO_THRESHOLD_1_8) != HAL_OK)
  {
    Error_Handler();
  }
  if (HAL_UARTEx_DisableFifoMode(&huart2) != HAL_OK)
  {
    Error_Handler();
  }

}

static void MX_DMA_Init(void)
{

  /* DMA controller clock enable */
  __HAL_RCC_DMA1_CLK_ENABLE();
  __HAL_RCC_DMA2_CLK_ENABLE();

  /* DMA interrupt init */
  /* DMA1_Stream0_IRQn interrupt configuration */
  HAL_NVIC_SetPriority(DMA1_Stream0_IRQn, 0, 0);
  HAL_NVIC_EnableIRQ(DMA1_Stream0_IRQn);
  /* DMA1_Stream1_IRQn interrupt configuration */
  HAL_NVIC_SetPriority(DMA1_Stream1_IRQn, 0, 0);
  HAL_NVIC_EnableIRQ(DMA1_Stream1_IRQn);
  /* DMA2_Stream0_IRQn interrupt configuration */
  HAL_NVIC_SetPriority(DMA2_Stream0_IRQn, 0, 0);
  HAL_NVIC_EnableIRQ(DMA2_Stream0_IRQn);

}

static void MX_GPIO_Init(void)
{
  GPIO_InitTypeDef GPIO_InitStruct = {0};

  /* GPIO Ports Clock Enable */
  __HAL_RCC_GPIOE_CLK_ENABLE();
  __HAL_RCC_GPIOC_CLK_ENABLE();
  __HAL_RCC_GPIOH_CLK_ENABLE();
  __HAL_RCC_GPIOA_CLK_ENABLE();
  __HAL_RCC_GPIOB_CLK_ENABLE();
  __HAL_RCC_GPIOD_CLK_ENABLE();

  /*Configure GPIO pin Output Level */
  HAL_GPIO_WritePin(GPIOC, GPIO_15_Pin|GPIO_14_Pin|GPIO_13_Pin|GPIO_12_Pin, GPIO_PIN_RESET);

  /*Configure GPIO pin Output Level */
  HAL_GPIO_WritePin(GPIO_11_GPIO_Port, GPIO_11_Pin, GPIO_PIN_RESET);

  /*Configure GPIO pin Output Level */
  HAL_GPIO_WritePin(GPIOE, GPIO_10_Pin|GPIO_09_Pin|GPIO_08_Pin, GPIO_PIN_RESET);

  /*Configure GPIO pin Output Level */
  HAL_GPIO_WritePin(GPIOD, GPIO_07_Pin|GPIO_06_Pin|GPIO_05_Pin|GPIO_04_Pin
                          |SPI_DISPLAY_REGISTER_SELECT_Pin|SPI_DISPLAY_RESET_Pin|GPIO_03_Pin|GPIO_02_Pin
                          |GPIO_01_Pin|GPIO_00_Pin, GPIO_PIN_RESET);

  /*Configure GPIO pins : GPIO_15_Pin GPIO_14_Pin GPIO_13_Pin GPIO_12_Pin */
  GPIO_InitStruct.Pin = GPIO_15_Pin|GPIO_14_Pin|GPIO_13_Pin|GPIO_12_Pin;
  GPIO_InitStruct.Mode = GPIO_MODE_OUTPUT_PP;
  GPIO_InitStruct.Pull = GPIO_NOPULL;
  GPIO_InitStruct.Speed = GPIO_SPEED_FREQ_LOW;
  HAL_GPIO_Init(GPIOC, &GPIO_InitStruct);

  /*Configure GPIO pin : SDCARD_CARD_DETECT_Pin */
  GPIO_InitStruct.Pin = SDCARD_CARD_DETECT_Pin;
  GPIO_InitStruct.Mode = GPIO_MODE_INPUT;
  GPIO_InitStruct.Pull = GPIO_NOPULL;
  HAL_GPIO_Init(SDCARD_CARD_DETECT_GPIO_Port, &GPIO_InitStruct);

  /*Configure GPIO pin : GPIO_11_Pin */
  GPIO_InitStruct.Pin = GPIO_11_Pin;
  GPIO_InitStruct.Mode = GPIO_MODE_OUTPUT_PP;
  GPIO_InitStruct.Pull = GPIO_NOPULL;
  GPIO_InitStruct.Speed = GPIO_SPEED_FREQ_LOW;
  HAL_GPIO_Init(GPIO_11_GPIO_Port, &GPIO_InitStruct);

  /*Configure GPIO pins : GPIO_10_Pin GPIO_09_Pin GPIO_08_Pin */
  GPIO_InitStruct.Pin = GPIO_10_Pin|GPIO_09_Pin|GPIO_08_Pin;
  GPIO_InitStruct.Mode = GPIO_MODE_OUTPUT_PP;
  GPIO_InitStruct.Pull = GPIO_NOPULL;
  GPIO_InitStruct.Speed = GPIO_SPEED_FREQ_LOW;
  HAL_GPIO_Init(GPIOE, &GPIO_InitStruct);

  /*Configure GPIO pins : GPIO_07_Pin GPIO_06_Pin GPIO_05_Pin GPIO_04_Pin
                           SPI_DISPLAY_REGISTER_SELECT_Pin SPI_DISPLAY_RESET_Pin GPIO_03_Pin GPIO_02_Pin
                           GPIO_01_Pin GPIO_00_Pin */
  GPIO_InitStruct.Pin = GPIO_07_Pin|GPIO_06_Pin|GPIO_05_Pin|GPIO_04_Pin
                          |SPI_DISPLAY_REGISTER_SELECT_Pin|SPI_DISPLAY_RESET_Pin|GPIO_03_Pin|GPIO_02_Pin
                          |GPIO_01_Pin|GPIO_00_Pin;
  GPIO_InitStruct.Mode = GPIO_MODE_OUTPUT_PP;
  GPIO_InitStruct.Pull = GPIO_NOPULL;
  GPIO_InitStruct.Speed = GPIO_SPEED_FREQ_LOW;
  HAL_GPIO_Init(GPIOD, &GPIO_InitStruct);

}

void Error_Handler(void)
{
  __disable_irq();
  while (1)
  {
  }
}
